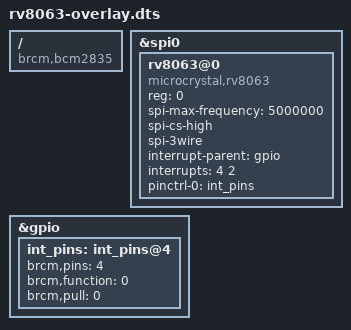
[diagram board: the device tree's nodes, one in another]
/dts-v1/;
/plugin/;

/ {
        compatible = "brcm,bcm2835";

        fragment@0 {
                target = <&spi0>;
                __overlay__ {
                        #address-cells = <1>;
			#size-cells = <0>;
                        status = "okay";

                        rv8063@0 {
                                compatible = "microcrystal,rv8063";
                                reg = <0>;
                                spi-max-frequency = <5000000>;
                                spi-cs-high;
                                spi-3wire;

                                interrupt-parent = <&gpio>;
                                interrupts = <4 2>;
                                pinctrl-0 = <&int_pins>;
                                pinctrl-names = "default";

                                status = "okay";
                        };
                };
        };

        fragment@99 {
		target = <&gpio>;
		__overlay__ {
			int_pins: int_pins@4 {
                                brcm,pins = <4>;
                                brcm,function = <0>; /* in */
                                brcm,pull = <0>; /* none */
			};
		};
	};

};
